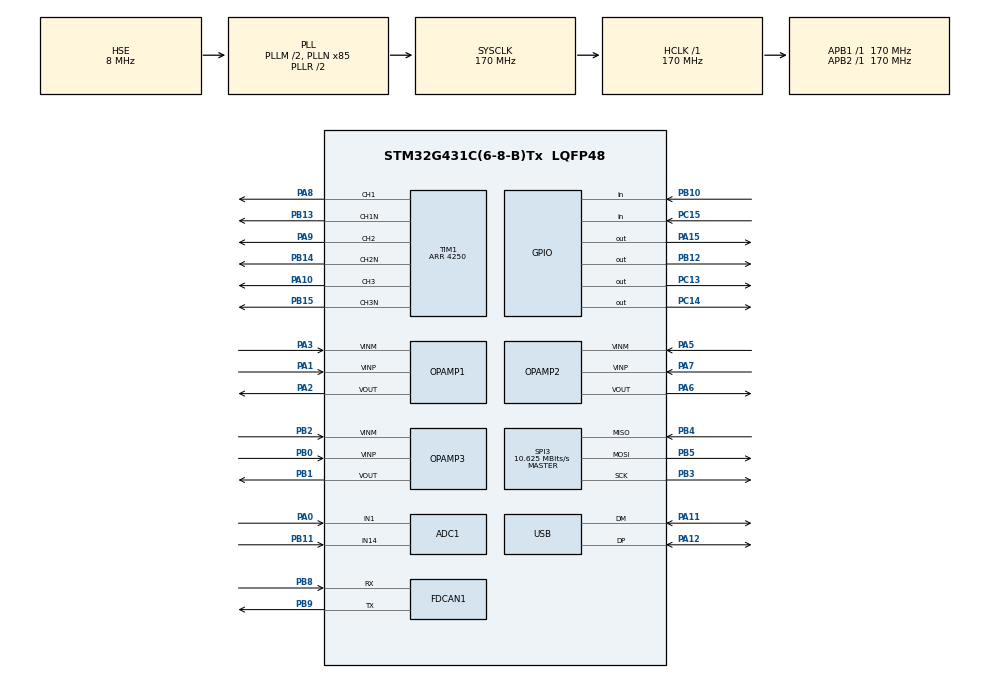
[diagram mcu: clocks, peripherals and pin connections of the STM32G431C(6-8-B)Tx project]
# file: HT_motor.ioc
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ADC1.Channel-0\#ChannelRegularConversion=ADC_CHANNEL_14
ADC1.EnableInjectedConversion=ENABLE
ADC1.ExternalTrigInjecConv=ADC_EXTERNALTRIGINJEC_T1_TRGO
ADC1.InjNumberOfConversion=2
ADC1.InjectedChannel-1\#ChannelInjectedConversion=ADC_CHANNEL_3
ADC1.InjectedChannel-2\#ChannelInjectedConversion=ADC_CHANNEL_1
ADC1.InjectedOffsetNumber-1\#ChannelInjectedConversion=ADC_OFFSET_NONE
ADC1.InjectedOffsetNumber-2\#ChannelInjectedConversion=ADC_OFFSET_NONE
ADC1.InjectedRank-1\#ChannelInjectedConversion=1
ADC1.InjectedRank-2\#ChannelInjectedConversion=2
ADC1.InjectedSamplingTime-1\#ChannelInjectedConversion=ADC_SAMPLETIME_6CYCLES_5
ADC1.InjectedSamplingTime-2\#ChannelInjectedConversion=ADC_SAMPLETIME_6CYCLES_5
ADC1.NbrOfConversion=1
ADC1.NbrOfConversionFlag=1
ADC1.OffsetNumber-0\#ChannelRegularConversion=ADC_OFFSET_NONE
ADC1.Rank-0\#ChannelRegularConversion=1
ADC1.Rank2_Channel=ADC_CHANNEL_1
ADC1.SamplingTime-0\#ChannelRegularConversion=ADC_SAMPLETIME_47CYCLES_5
ADC1.master=1
ADC2.Channel-3\#ChannelRegularConversion=ADC_CHANNEL_3
ADC2.EnableInjectedConversion=ENABLE
ADC2.ExternalTrigInjecConv=ADC_EXTERNALTRIGINJEC_T1_TRGO
ADC2.InjNumberOfConversion=1
ADC2.InjectedChannel-4\#ChannelInjectedConversion=ADC_CHANNEL_3
ADC2.InjectedOffsetNumber-4\#ChannelInjectedConversion=ADC_OFFSET_NONE
ADC2.InjectedRank-4\#ChannelInjectedConversion=1
ADC2.InjectedSamplingTime-4\#ChannelInjectedConversion=ADC_SAMPLETIME_6CYCLES_5
ADC2.NbrOfConversionFlag=1
ADC2.OffsetNumber-3\#ChannelRegularConversion=ADC_OFFSET_NONE
ADC2.Rank-3\#ChannelRegularConversion=1
ADC2.SamplingTime-3\#ChannelRegularConversion=ADC_SAMPLETIME_2CYCLES_5
Dma.Request0=SPI3_RX
Dma.Request1=SPI3_TX
Dma.SPI3_RX.0.Direction=DMA_PERIPH_TO_MEMORY
Dma.SPI3_RX.0.EventEnable=DISABLE
Dma.SPI3_RX.0.Instance=DMA1_Channel1
Dma.SPI3_RX.0.MemDataAlignment=DMA_MDATAALIGN_BYTE
Dma.SPI3_RX.0.MemInc=DMA_MINC_DISABLE
Dma.SPI3_RX.0.Mode=DMA_NORMAL
Dma.SPI3_RX.0.PeriphDataAlignment=DMA_PDATAALIGN_BYTE
Dma.SPI3_RX.0.PeriphInc=DMA_PINC_DISABLE
Dma.SPI3_RX.0.Polarity=HAL_DMAMUX_REQ_GEN_RISING
Dma.SPI3_RX.0.Priority=DMA_PRIORITY_LOW
Dma.SPI3_RX.0.RequestNumber=1
Dma.SPI3_RX.0.SignalID=NONE
Dma.SPI3_RX.0.SyncEnable=DISABLE
Dma.SPI3_RX.0.SyncPolarity=HAL_DMAMUX_SYNC_NO_EVENT
Dma.SPI3_RX.0.SyncRequestNumber=1
Dma.SPI3_RX.0.SyncSignalID=NONE
Dma.SPI3_TX.1.Direction=DMA_MEMORY_TO_PERIPH
Dma.SPI3_TX.1.EventEnable=DISABLE
Dma.SPI3_TX.1.Instance=DMA1_Channel2
Dma.SPI3_TX.1.MemDataAlignment=DMA_MDATAALIGN_BYTE
Dma.SPI3_TX.1.MemInc=DMA_MINC_ENABLE
Dma.SPI3_TX.1.Mode=DMA_NORMAL
Dma.SPI3_TX.1.PeriphDataAlignment=DMA_PDATAALIGN_BYTE
Dma.SPI3_TX.1.PeriphInc=DMA_PINC_DISABLE
Dma.SPI3_TX.1.Polarity=HAL_DMAMUX_REQ_GEN_RISING
Dma.SPI3_TX.1.Priority=DMA_PRIORITY_LOW
Dma.SPI3_TX.1.RequestNumber=1
Dma.SPI3_TX.1.SignalID=NONE
Dma.SPI3_TX.1.SyncEnable=DISABLE
Dma.SPI3_TX.1.SyncPolarity=HAL_DMAMUX_SYNC_NO_EVENT
Dma.SPI3_TX.1.SyncRequestNumber=1
Dma.SPI3_TX.1.SyncSignalID=NONE
FDCAN1.AutoRetransmission=ENABLE
FDCAN1.CalculateBaudRateNominal=1000000
FDCAN1.CalculateTimeBitNominal=1000
FDCAN1.CalculateTimeQuantumNominal=100.0
FDCAN1.NominalPrescaler=17
FDCAN1.NominalTimeSeg1=8
Mcu.Family=STM32G4
Mcu.Name=STM32G431C(6-8-B)Tx
Mcu.Package=LQFP48
NVIC.ADC1_2_IRQn=true\:1\:0\:true\:false\:true\:true\:true\:true
NVIC.DMA1_Channel1_IRQn=true\:0\:0\:false\:false\:true\:false\:true\:true
NVIC.DMA1_Channel2_IRQn=true\:0\:0\:false\:false\:true\:false\:true\:true
NVIC.FDCAN1_IT0_IRQn=true\:4\:0\:true\:false\:true\:true\:true\:true
NVIC.FDCAN1_IT1_IRQn=true\:4\:0\:true\:false\:true\:true\:true\:true
NVIC.PriorityGroup=NVIC_PRIORITYGROUP_4
NVIC.SPI3_IRQn=true\:3\:0\:true\:false\:true\:true\:true\:true
NVIC.TIM2_IRQn=true\:2\:0\:true\:false\:true\:true\:true\:true
NVIC.TIM6_DAC_IRQn=true\:0\:0\:false\:false\:true\:true\:true\:true
NVIC.USB_HP_IRQn=true\:5\:0\:true\:false\:true\:true\:true\:true
NVIC.USB_LP_IRQn=true\:5\:0\:true\:false\:true\:true\:true\:true
PA0.Mode=IN1-Single-Ended
PA0.Signal=ADC1_IN1
PA1.Mode=Standalone
PA1.Signal=OPAMP1_VINP
PA10.Signal=S_TIM1_CH3
PA11.Mode=Device
PA11.Signal=USB_DM
PA12.Mode=Device
PA12.Signal=USB_DP
PA13.Mode=Serial_Wire
PA13.Signal=SYS_JTMS-SWDIO
PA14.Mode=Serial_Wire
PA14.Signal=SYS_JTCK-SWCLK
PA15.GPIO_ModeDefaultOutputPP=GPIO_MODE_OUTPUT_PP
PA15.GPIO_PuPd=GPIO_PULLUP
PA15.GPIO_Speed=GPIO_SPEED_FREQ_VERY_HIGH
PA15.PinState=GPIO_PIN_SET
PA15.Signal=GPIO_Output
PA2.Signal=SharedAnalog_PA2
PA3.Mode=Standalone
PA3.Signal=OPAMP1_VINM
PA5.Mode=Standalone
PA5.Signal=OPAMP2_VINM
PA6.Signal=SharedAnalog_PA6
PA7.Mode=Standalone
PA7.Signal=OPAMP2_VINP
PA8.Signal=S_TIM1_CH1
PA9.Signal=S_TIM1_CH2
PB0.Mode=Standalone
PB0.Signal=OPAMP3_VINP
PB1.Signal=SharedAnalog_PB1
PB10.GPIO_PuPd=GPIO_PULLUP
PB10.Signal=GPIO_Input
PB11.Mode=IN14-Single-Ended
PB11.Signal=ADC1_IN14
PB12.Signal=GPIO_Output
PB13.Mode=PWM Generation1 CH1 CH1N
PB13.Signal=TIM1_CH1N
PB14.Mode=PWM Generation2 CH2 CH2N
PB14.Signal=TIM1_CH2N
PB15.Mode=PWM Generation3 CH3 CH3N
PB15.Signal=TIM1_CH3N
PB2.Mode=Standalone
PB2.Signal=OPAMP3_VINM
PB3.Mode=Full_Duplex_Master
PB3.Signal=SPI3_SCK
PB4.Mode=Full_Duplex_Master
PB4.Signal=SPI3_MISO
PB5.Mode=Full_Duplex_Master
PB5.Signal=SPI3_MOSI
PB8-BOOT0.Mode=FDCAN_Activate
PB8-BOOT0.Signal=FDCAN1_RX
PB9.Mode=FDCAN_Activate
PB9.Signal=FDCAN1_TX
PC13.GPIO_PuPd=GPIO_NOPULL
PC13.PinState=GPIO_PIN_SET
PC13.Signal=GPIO_Output
PC14-OSC32_IN.Signal=GPIO_Output
PC15-OSC32_OUT.Signal=GPIO_Input
PF0-OSC_IN.Mode=HSE-External-Oscillator
PF0-OSC_IN.Signal=RCC_OSC_IN
PF1-OSC_OUT.Mode=HSE-External-Oscillator
PF1-OSC_OUT.Signal=RCC_OSC_OUT
ProjectManager.HeapSize=0x200
ProjectManager.StackSize=0x400
ProjectManager.TargetToolchain=MDK-ARM V5.32
RCC.ADC12Freq_Value=170000000
RCC.AHBFreq_Value=170000000
RCC.APB1Freq_Value=170000000
RCC.APB1TimFreq_Value=170000000
RCC.APB2Freq_Value=170000000
RCC.APB2TimFreq_Value=170000000
RCC.CK48CLockSelection=RCC_USBCLKSOURCE_HSI48
RCC.CortexFreq_Value=170000000
RCC.EXTERNAL_CLOCK_VALUE=12288000
RCC.HCLKFreq_Value=170000000
RCC.HSE_VALUE=8000000
RCC.HSI48_VALUE=48000000
RCC.HSI_VALUE=16000000
RCC.LSE_VALUE=32768
RCC.PLLM=RCC_PLLM_DIV2
RCC.PLLN=85
RCC.PLLSourceVirtual=RCC_PLLSOURCE_HSE
RCC.SYSCLKFreq_VALUE=170000000
RCC.SYSCLKSource=RCC_SYSCLKSOURCE_PLLCLK
RCC.USBFreq_Value=48000000
RCC.VCOOutputFreq_Value=340000000
SH.S_TIM1_CH1.0=TIM1_CH1,PWM Generation1 CH1 CH1N
SH.S_TIM1_CH2.0=TIM1_CH2,PWM Generation2 CH2 CH2N
SH.S_TIM1_CH3.0=TIM1_CH3,PWM Generation3 CH3 CH3N
SH.SharedAnalog_PA2.0=OPAMP1_VOUT,Standalone
SH.SharedAnalog_PA2.1=ADC1_IN3,IN3-Single-Ended
SH.SharedAnalog_PA6.0=OPAMP2_VOUT,Standalone
SH.SharedAnalog_PA6.1=ADC2_IN3,IN3-Single-Ended
SH.SharedAnalog_PB1.0=OPAMP3_VOUT,Standalone
SH.SharedAnalog_PB1.1=ADC1_IN12,IN12-Single-Ended
SPI3.BaudRatePrescaler=SPI_BAUDRATEPRESCALER_16
SPI3.CLKPhase=SPI_PHASE_2EDGE
SPI3.CLKPolarity=SPI_POLARITY_HIGH
SPI3.CalculateBaudRate=10.625 MBits/s
SPI3.DataSize=SPI_DATASIZE_8BIT
SPI3.Direction=SPI_DIRECTION_2LINES
SPI3.Mode=SPI_MODE_MASTER
SPI3.VirtualType=VM_MASTER
TIM1.AutoReloadPreload=TIM_AUTORELOAD_PRELOAD_ENABLE
TIM1.Channel-PWM\ Generation1\ CH1\ CH1N=TIM_CHANNEL_1
TIM1.Channel-PWM\ Generation2\ CH2\ CH2N=TIM_CHANNEL_2
TIM1.Channel-PWM\ Generation3\ CH3\ CH3N=TIM_CHANNEL_3
TIM1.CounterMode=TIM_COUNTERMODE_CENTERALIGNED1
TIM1.DeadTime=85
TIM1.PeriodNoDither=4250
TIM1.RepetitionCounter=1
TIM1.TIM_MasterOutputTrigger=TIM_TRGO_UPDATE
TIM2.AutoReloadPreload=TIM_AUTORELOAD_PRELOAD_ENABLE
TIM2.PeriodNoDither=17000-1
TIM2.Prescaler=9
TIM6.AutoReloadPreload=TIM_AUTORELOAD_PRELOAD_ENABLE
TIM6.PeriodNoDither=9999
TIM6.Prescaler=169
USB_DEVICE.CLASS_NAME_FS=CDC
USB_DEVICE.USBD_LPM_ENABLED=0
USB_DEVICE.VirtualMode=Cdc
USB_DEVICE.VirtualModeFS=Cdc_FS
VP_SYS_VS_DBSignals.Mode=DisableDeadBatterySignals
VP_TIM1_VS_ClockSourceINT.Mode=Internal
VP_TIM2_VS_ClockSourceINT.Mode=Internal
VP_TIM6_VS_ClockSourceINT.Mode=Enable_Timer
VP_USB_DEVICE_VS_USB_DEVICE_CDC_FS.Mode=CDC_FS
board=custom

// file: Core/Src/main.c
/* USER CODE BEGIN Header */
/**
  ******************************************************************************
  * @file           : main.c
  * @brief          : Main program body
  ******************************************************************************
  * @attention
  *
  * Copyright (c) 2026 STMicroelectronics.
  * All rights reserved.
  *
  * This software is licensed under terms that can be found in the LICENSE file
  * in the root directory of this software component.
  * If no LICENSE file comes with this software, it is provided AS-IS.
  *
  ******************************************************************************
  */
/* USER CODE END Header */
#include "main.h"
#include "adc.h"
#include "dma.h"
#include "fdcan.h"
#include "opamp.h"
#include "spi.h"
#include "tim.h"
#include "usb_device.h"
#include "gpio.h"

/* USER CODE BEGIN Includes */
#include "motor_global.h"
/* USER CODE END Includes */

void SystemClock_Config(void);

int main(void)
{

  /* MCU Configuration--------------------------------------------------------*/

  /* Reset of all peripherals, Initializes the Flash interface and the Systick. */
  HAL_Init();

  /* Configure the system clock */
  SystemClock_Config();

  /* Initialize all configured peripherals */
  MX_GPIO_Init();
  MX_DMA_Init();
  MX_ADC1_Init();
  MX_ADC2_Init();
  MX_FDCAN1_Init();
  MX_SPI3_Init();
  MX_TIM1_Init();
  MX_TIM2_Init();
  MX_USB_Device_Init();
  MX_OPAMP1_Init();
  MX_OPAMP3_Init();
  MX_OPAMP2_Init();
  MX_TIM6_Init();
  /* USER CODE BEGIN 2 */
  global_init();
  /* USER CODE END 2 */

  /* Infinite loop */
  while (1)
  {

    /* USER CODE BEGIN 3 */
    global_loop();
  }
  /* USER CODE END 3 */
}

void SystemClock_Config(void)
{
  RCC_OscInitTypeDef RCC_OscInitStruct = {0};
  RCC_ClkInitTypeDef RCC_ClkInitStruct = {0};

  /** Configure the main internal regulator output voltage
  */
  HAL_PWREx_ControlVoltageScaling(PWR_REGULATOR_VOLTAGE_SCALE1_BOOST);

  /** Initializes the RCC Oscillators according to the specified parameters
  * in the RCC_OscInitTypeDef structure.
  */
  RCC_OscInitStruct.OscillatorType = RCC_OSCILLATORTYPE_HSI48|RCC_OSCILLATORTYPE_HSE;
  RCC_OscInitStruct.HSEState = RCC_HSE_ON;
  RCC_OscInitStruct.HSI48State = RCC_HSI48_ON;
  RCC_OscInitStruct.PLL.PLLState = RCC_PLL_ON;
  RCC_OscInitStruct.PLL.PLLSource = RCC_PLLSOURCE_HSE;
  RCC_OscInitStruct.PLL.PLLM = RCC_PLLM_DIV2;
  RCC_OscInitStruct.PLL.PLLN = 85;
  RCC_OscInitStruct.PLL.PLLP = RCC_PLLP_DIV2;
  RCC_OscInitStruct.PLL.PLLQ = RCC_PLLQ_DIV2;
  RCC_OscInitStruct.PLL.PLLR = RCC_PLLR_DIV2;
  if (HAL_RCC_OscConfig(&RCC_OscInitStruct) != HAL_OK)
  {
    Error_Handler();
  }

  /** Initializes the CPU, AHB and APB buses clocks
  */
  RCC_ClkInitStruct.ClockType = RCC_CLOCKTYPE_HCLK|RCC_CLOCKTYPE_SYSCLK
                              |RCC_CLOCKTYPE_PCLK1|RCC_CLOCKTYPE_PCLK2;
  RCC_ClkInitStruct.SYSCLKSource = RCC_SYSCLKSOURCE_PLLCLK;
  RCC_ClkInitStruct.AHBCLKDivider = RCC_SYSCLK_DIV1;
  RCC_ClkInitStruct.APB1CLKDivider = RCC_HCLK_DIV1;
  RCC_ClkInitStruct.APB2CLKDivider = RCC_HCLK_DIV1;

  if (HAL_RCC_ClockConfig(&RCC_ClkInitStruct, FLASH_LATENCY_4) != HAL_OK)
  {
    Error_Handler();
  }
}

void Error_Handler(void)
{
  __disable_irq();
  while (1)
  {
  }
}
